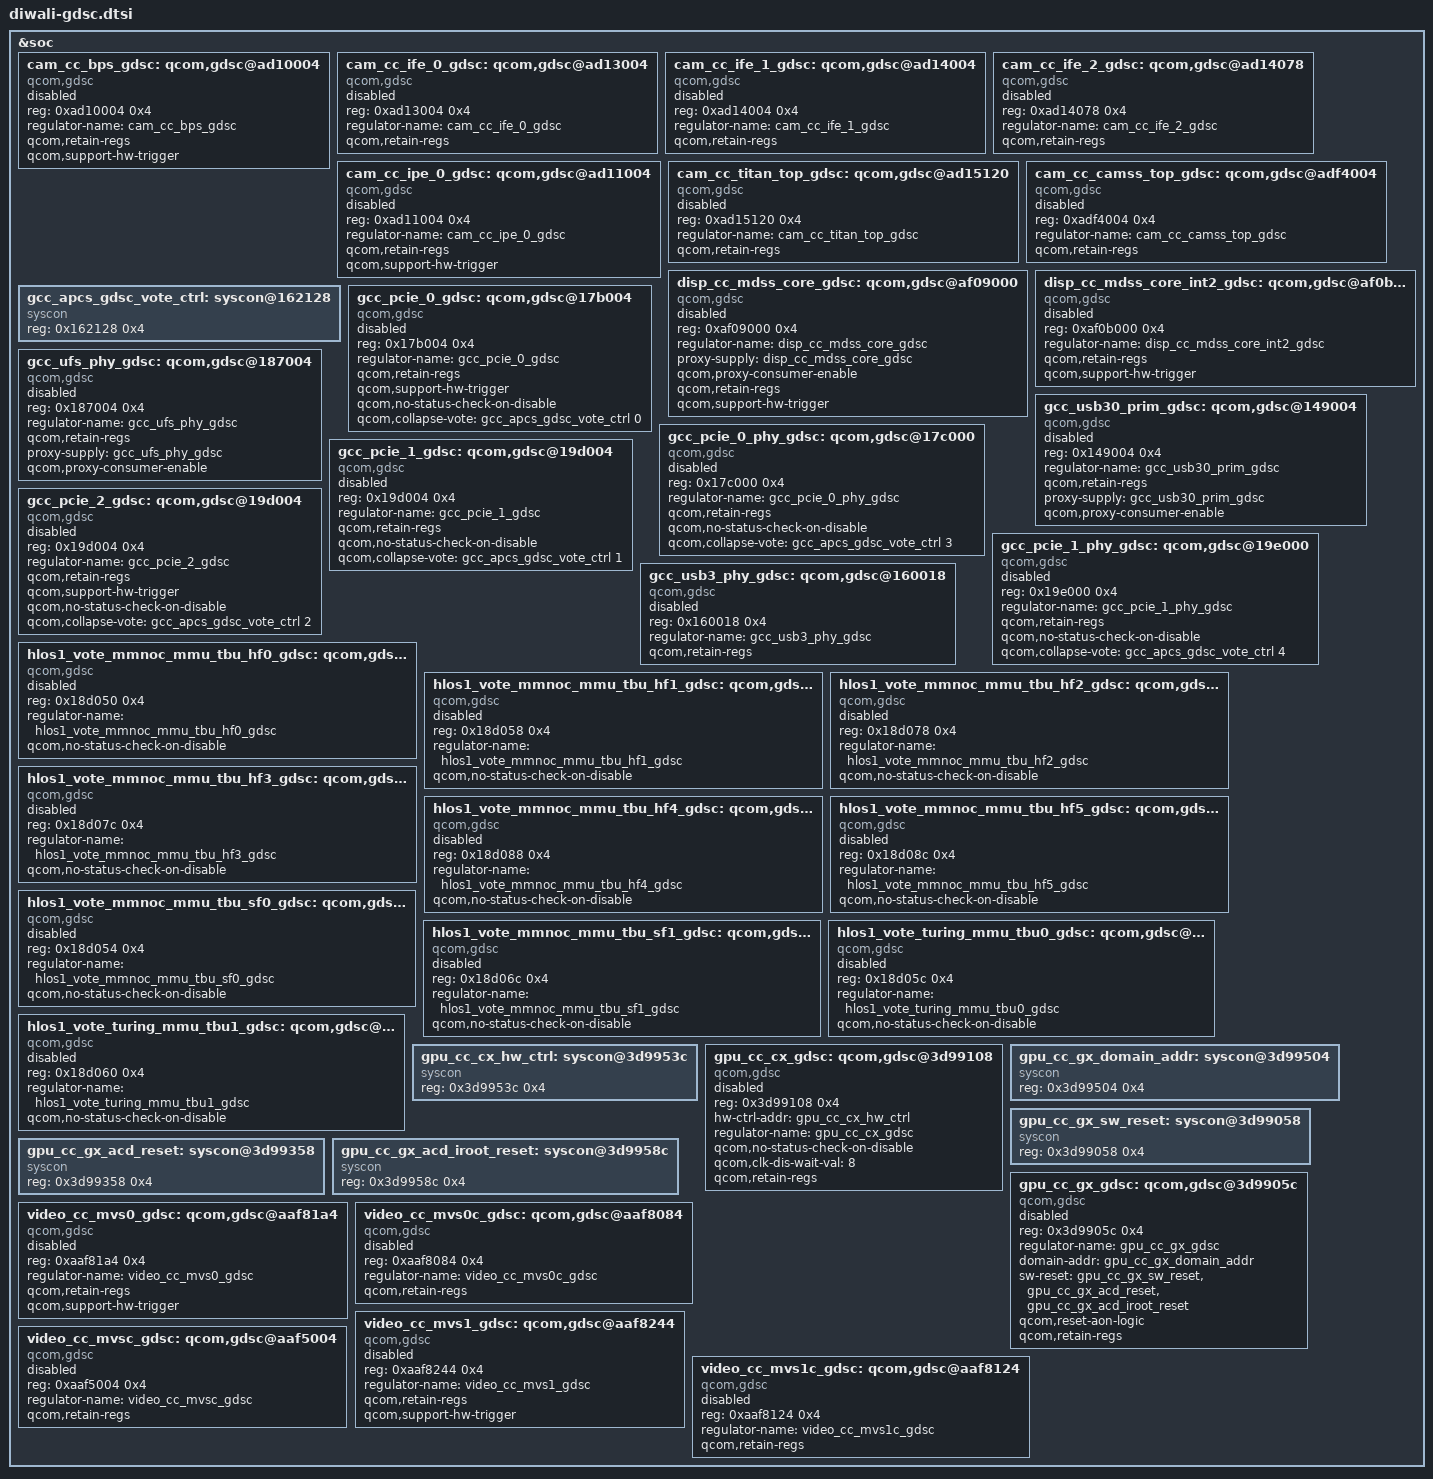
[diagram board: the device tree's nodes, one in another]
&soc {
	/* CAM_CC GDSCs */
	cam_cc_bps_gdsc: qcom,gdsc@ad10004 {
		compatible = "qcom,gdsc";
		reg = <0xad10004 0x4>;
		regulator-name = "cam_cc_bps_gdsc";
		qcom,retain-regs;
		qcom,support-hw-trigger;
		status = "disabled";
	};

	cam_cc_ife_0_gdsc: qcom,gdsc@ad13004 {
		compatible = "qcom,gdsc";
		reg = <0xad13004 0x4>;
		regulator-name = "cam_cc_ife_0_gdsc";
		qcom,retain-regs;
		status = "disabled";
	};

	cam_cc_ife_1_gdsc: qcom,gdsc@ad14004 {
		compatible = "qcom,gdsc";
		reg = <0xad14004 0x4>;
		regulator-name = "cam_cc_ife_1_gdsc";
		qcom,retain-regs;
		status = "disabled";
	};

	cam_cc_ife_2_gdsc: qcom,gdsc@ad14078 {
		compatible = "qcom,gdsc";
		reg = <0xad14078 0x4>;
		regulator-name = "cam_cc_ife_2_gdsc";
		qcom,retain-regs;
		status = "disabled";
	};

	cam_cc_ipe_0_gdsc: qcom,gdsc@ad11004 {
		compatible = "qcom,gdsc";
		reg = <0xad11004 0x4>;
		regulator-name = "cam_cc_ipe_0_gdsc";
		qcom,retain-regs;
		qcom,support-hw-trigger;
		status = "disabled";
	};

	cam_cc_titan_top_gdsc: qcom,gdsc@ad15120 {
		compatible = "qcom,gdsc";
		reg = <0xad15120 0x4>;
		regulator-name = "cam_cc_titan_top_gdsc";
		qcom,retain-regs;
		status = "disabled";
	};

	cam_cc_camss_top_gdsc: qcom,gdsc@adf4004 {
		compatible = "qcom,gdsc";
		reg = <0xadf4004 0x4>;
		regulator-name = "cam_cc_camss_top_gdsc";
		qcom,retain-regs;
		status = "disabled";
	};

	/* DISP_CC GDSCs */
	disp_cc_mdss_core_gdsc: qcom,gdsc@af09000 {
		compatible = "qcom,gdsc";
		reg = <0xaf09000 0x4>;
		regulator-name = "disp_cc_mdss_core_gdsc";
		proxy-supply = <&disp_cc_mdss_core_gdsc>;
		qcom,proxy-consumer-enable;
		qcom,retain-regs;
		qcom,support-hw-trigger;
		status = "disabled";
	};

	disp_cc_mdss_core_int2_gdsc: qcom,gdsc@af0b000 {
		compatible = "qcom,gdsc";
		reg = <0xaf0b000 0x4>;
		regulator-name = "disp_cc_mdss_core_int2_gdsc";
		qcom,retain-regs;
		qcom,support-hw-trigger;
		status = "disabled";
	};

	gcc_apcs_gdsc_vote_ctrl: syscon@162128 {
		compatible = "syscon";
		reg = <0x162128 0x4>;
	};

	/* GCC GDSCs */
	gcc_pcie_0_gdsc: qcom,gdsc@17b004 {
		compatible = "qcom,gdsc";
		reg = <0x17b004 0x4>;
		regulator-name = "gcc_pcie_0_gdsc";
		qcom,retain-regs;
		qcom,support-hw-trigger;
		qcom,no-status-check-on-disable;
		qcom,collapse-vote = <&gcc_apcs_gdsc_vote_ctrl 0>;
		status = "disabled";
	};

	gcc_ufs_phy_gdsc: qcom,gdsc@187004 {
		compatible = "qcom,gdsc";
		reg = <0x187004 0x4>;
		regulator-name = "gcc_ufs_phy_gdsc";
		qcom,retain-regs;
		proxy-supply = <&gcc_ufs_phy_gdsc>;
		qcom,proxy-consumer-enable;
		status = "disabled";
	};

	gcc_usb30_prim_gdsc: qcom,gdsc@149004 {
		compatible = "qcom,gdsc";
		reg = <0x149004 0x4>;
		regulator-name = "gcc_usb30_prim_gdsc";
		qcom,retain-regs;
		proxy-supply = <&gcc_usb30_prim_gdsc>;
		qcom,proxy-consumer-enable;
		status = "disabled";
	};

	gcc_pcie_0_phy_gdsc: qcom,gdsc@17c000 {
		compatible = "qcom,gdsc";
		reg = <0x17c000 0x4>;
		regulator-name = "gcc_pcie_0_phy_gdsc";
		qcom,retain-regs;
		qcom,no-status-check-on-disable;
		qcom,collapse-vote = <&gcc_apcs_gdsc_vote_ctrl 3>;
		status = "disabled";
	};

	gcc_pcie_1_gdsc: qcom,gdsc@19d004 {
		compatible = "qcom,gdsc";
		reg = <0x19d004 0x4>;
		regulator-name = "gcc_pcie_1_gdsc";
		qcom,retain-regs;
		qcom,no-status-check-on-disable;
		qcom,collapse-vote = <&gcc_apcs_gdsc_vote_ctrl 1>;
		status = "disabled";
	};

	gcc_pcie_1_phy_gdsc: qcom,gdsc@19e000 {
		compatible = "qcom,gdsc";
		reg = <0x19e000 0x4>;
		regulator-name = "gcc_pcie_1_phy_gdsc";
		qcom,retain-regs;
		qcom,no-status-check-on-disable;
		qcom,collapse-vote = <&gcc_apcs_gdsc_vote_ctrl 4>;
		status = "disabled";
	};

	gcc_pcie_2_gdsc: qcom,gdsc@19d004 {
		compatible = "qcom,gdsc";
		reg = <0x19d004 0x4>;
		regulator-name = "gcc_pcie_2_gdsc";
		qcom,retain-regs;
		qcom,support-hw-trigger;
		qcom,no-status-check-on-disable;
		qcom,collapse-vote = <&gcc_apcs_gdsc_vote_ctrl 2>;
		status = "disabled";
	};

	gcc_usb3_phy_gdsc: qcom,gdsc@160018 {
		compatible = "qcom,gdsc";
		reg = <0x160018 0x4>;
		regulator-name = "gcc_usb3_phy_gdsc";
		qcom,retain-regs;
		status = "disabled";
	};

	hlos1_vote_mmnoc_mmu_tbu_hf0_gdsc: qcom,gdsc@18d050 {
		compatible = "qcom,gdsc";
		reg = <0x18d050 0x4>;
		regulator-name = "hlos1_vote_mmnoc_mmu_tbu_hf0_gdsc";
		qcom,no-status-check-on-disable;
		status = "disabled";
	};

	hlos1_vote_mmnoc_mmu_tbu_hf1_gdsc: qcom,gdsc@18d058 {
		compatible = "qcom,gdsc";
		reg = <0x18d058 0x4>;
		regulator-name = "hlos1_vote_mmnoc_mmu_tbu_hf1_gdsc";
		qcom,no-status-check-on-disable;
		status = "disabled";
	};

	hlos1_vote_mmnoc_mmu_tbu_hf2_gdsc: qcom,gdsc@18d078 {
		compatible = "qcom,gdsc";
		reg = <0x18d078 0x4>;
		regulator-name = "hlos1_vote_mmnoc_mmu_tbu_hf2_gdsc";
		qcom,no-status-check-on-disable;
		status = "disabled";
	};

	hlos1_vote_mmnoc_mmu_tbu_hf3_gdsc: qcom,gdsc@18d07c {
		compatible = "qcom,gdsc";
		reg = <0x18d07c 0x4>;
		regulator-name = "hlos1_vote_mmnoc_mmu_tbu_hf3_gdsc";
		qcom,no-status-check-on-disable;
		status = "disabled";
	};

	hlos1_vote_mmnoc_mmu_tbu_hf4_gdsc: qcom,gdsc@18d088 {
		compatible = "qcom,gdsc";
		reg = <0x18d088 0x4>;
		regulator-name = "hlos1_vote_mmnoc_mmu_tbu_hf4_gdsc";
		qcom,no-status-check-on-disable;
		status = "disabled";
	};

	hlos1_vote_mmnoc_mmu_tbu_hf5_gdsc: qcom,gdsc@18d08c {
		compatible = "qcom,gdsc";
		reg = <0x18d08c 0x4>;
		regulator-name = "hlos1_vote_mmnoc_mmu_tbu_hf5_gdsc";
		qcom,no-status-check-on-disable;
		status = "disabled";
	};

	hlos1_vote_mmnoc_mmu_tbu_sf0_gdsc: qcom,gdsc@18d054 {
		compatible = "qcom,gdsc";
		reg = <0x18d054 0x4>;
		regulator-name = "hlos1_vote_mmnoc_mmu_tbu_sf0_gdsc";
		qcom,no-status-check-on-disable;
		status = "disabled";
	};

	hlos1_vote_mmnoc_mmu_tbu_sf1_gdsc: qcom,gdsc@18d06c {
		compatible = "qcom,gdsc";
		reg = <0x18d06c 0x4>;
		regulator-name = "hlos1_vote_mmnoc_mmu_tbu_sf1_gdsc";
		qcom,no-status-check-on-disable;
		status = "disabled";
	};

	hlos1_vote_turing_mmu_tbu0_gdsc: qcom,gdsc@18d05c {
		compatible = "qcom,gdsc";
		reg = <0x18d05c 0x4>;
		regulator-name = "hlos1_vote_turing_mmu_tbu0_gdsc";
		qcom,no-status-check-on-disable;
		status = "disabled";
	};

	hlos1_vote_turing_mmu_tbu1_gdsc: qcom,gdsc@18d060 {
		compatible = "qcom,gdsc";
		reg = <0x18d060 0x4>;
		regulator-name = "hlos1_vote_turing_mmu_tbu1_gdsc";
		qcom,no-status-check-on-disable;
		status = "disabled";
	};

	/* GPU_CC GDSCs */
	gpu_cc_cx_hw_ctrl: syscon@3d9953c {
		compatible = "syscon";
		reg = <0x3d9953c 0x4>;
	};

	/* GPU_CC GDSCs */
	gpu_cc_cx_gdsc: qcom,gdsc@3d99108 {
		compatible = "qcom,gdsc";
		reg = <0x3d99108 0x4>;
		hw-ctrl-addr = <&gpu_cc_cx_hw_ctrl>;
		regulator-name = "gpu_cc_cx_gdsc";
		qcom,no-status-check-on-disable;
		qcom,clk-dis-wait-val = <8>;
		qcom,retain-regs;
		status = "disabled";
	};

	gpu_cc_gx_domain_addr: syscon@3d99504 {
		compatible = "syscon";
		reg = <0x3d99504 0x4>;
	};

	gpu_cc_gx_sw_reset: syscon@3d99058 {
		compatible = "syscon";
		reg = <0x3d99058 0x4>;
	};

	gpu_cc_gx_acd_reset: syscon@3d99358 {
		compatible = "syscon";
		reg = <0x3d99358 0x4>;
	};

	gpu_cc_gx_acd_iroot_reset: syscon@3d9958c {
		compatible = "syscon";
		reg = <0x3d9958c 0x4>;
	};

	gpu_cc_gx_gdsc: qcom,gdsc@3d9905c {
		compatible = "qcom,gdsc";
		reg = <0x3d9905c 0x4>;
		regulator-name = "gpu_cc_gx_gdsc";
		domain-addr = <&gpu_cc_gx_domain_addr>;
		sw-reset = <&gpu_cc_gx_sw_reset>,
			   <&gpu_cc_gx_acd_reset>,
			   <&gpu_cc_gx_acd_iroot_reset>;
		qcom,reset-aon-logic;
		qcom,retain-regs;
		status = "disabled";
	};

	/* VIDEO_CC GDSCs */
	video_cc_mvs0_gdsc: qcom,gdsc@aaf81a4 {
		compatible = "qcom,gdsc";
		reg = <0xaaf81a4 0x4>;
		regulator-name = "video_cc_mvs0_gdsc";
		qcom,retain-regs;
		qcom,support-hw-trigger;
		status = "disabled";
	};

	video_cc_mvs0c_gdsc: qcom,gdsc@aaf8084 {
		compatible = "qcom,gdsc";
		reg = <0xaaf8084 0x4>;
		regulator-name = "video_cc_mvs0c_gdsc";
		qcom,retain-regs;
		status = "disabled";
	};

	video_cc_mvs1_gdsc: qcom,gdsc@aaf8244 {
		compatible = "qcom,gdsc";
		reg = <0xaaf8244 0x4>;
		regulator-name = "video_cc_mvs1_gdsc";
		qcom,retain-regs;
		qcom,support-hw-trigger;
		status = "disabled";
	};

	video_cc_mvs1c_gdsc: qcom,gdsc@aaf8124 {
		compatible = "qcom,gdsc";
		reg = <0xaaf8124 0x4>;
		regulator-name = "video_cc_mvs1c_gdsc";
		qcom,retain-regs;
		status = "disabled";
	};

	video_cc_mvsc_gdsc: qcom,gdsc@aaf5004 {
		compatible = "qcom,gdsc";
		reg = <0xaaf5004 0x4>;
		regulator-name = "video_cc_mvsc_gdsc";
		qcom,retain-regs;
		status = "disabled";
	};
};
